# STM32H5F5 register map
File version: 1.0
CPU: CM33 r0p0, little endian, MPU, FPU, 4 interrupt priority bits
Registers are 32-bit, read-write, reset 0x0 unless marked. A register's access mark holds for its fields unless they carry their own. Offsets are from the block's base; [hi:lo] are bit positions; 'fields as' and 'values as' point back to an identical list.

## OCTOSPI1 — OCTOSPI1 register block
Base 0x47001400
Same registers: OCTOSPI2 0x47002400, OCTOSPI1_S 0x57001400, OCTOSPI2_S 0x57002400
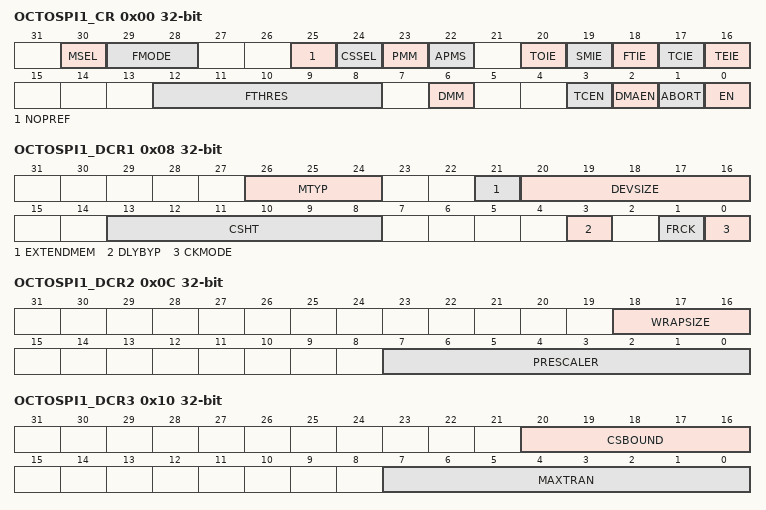
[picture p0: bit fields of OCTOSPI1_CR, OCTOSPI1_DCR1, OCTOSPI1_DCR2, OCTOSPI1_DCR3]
0x00 OCTOSPI1_CR — OCTOSPI control register
  [30] MSEL — External memory select
    0=External memory 1 selected (data exchanged over IO[3:0]); 1=External memory 2 selected (data exchanged over IO[7:4])
  [29:28] FMODE — Functional mode
    0=Indirect-write mode; 1=Indirect-read mode; 2=Automatic status-polling mode (relevant in regular-command protocol only); 3=Memory-mapped mode
  [25] NOPREF — No prefetch data
    0=Automatic prefetch enabled; 1=Automatic prefetch disabled
  [24] CSSEL — Chip-select selection
    0=NCS I/O manager input is copied to NCS1 I/O manager output; 1=NCS I/O manager input is copied to NCS2 I/O manager output
  [23] PMM — Polling match mode
    0=AND-match mode, SMF is set if all the unmasked bits received from the device match the corresponding bits in the match register; 1=OR-match mode, SMF is set if any of the unmasked bits received from the device matches its corresponding bit in the match register
  [22] APMS — Automatic status-polling mode stop
    0=Automatic status-polling mode is stopped only by abort or by disabling the OCTOSPI; 1=Automatic status-polling mode stops as soon as there is a match
  [20] TOIE — Timeout interrupt enable
    0=Interrupt disabled; 1=Interrupt enabled
  [19] SMIE — Status-match interrupt enable
    0=Interrupt disabled; 1=Interrupt enabled
  [18] FTIE — FIFO threshold interrupt enable
    0=Interrupt disabled; 1=Interrupt enabled
  [17] TCIE — Transfer complete interrupt enable
    0=Interrupt disabled; 1=Interrupt enabled
  [16] TEIE — Transfer error interrupt enable
    0=Interrupt disabled; 1=Interrupt enabled
  [12:8] FTHRES — FIFO threshold level
    0=FTF is set if there are one or more free bytes available to be written to in the FIFO inindirect-write mode, or if there are one or more valid bytes can be read from the FIFO inindirect-read mode; 1=FTF is set if there are two or more free bytes available to be written to in the FIFO inindirect-write mode, or if there are two or more valid bytes can be read from the FIFO inindirect-read mode; 31=FTF is set if there are 32 free bytes available to be written to in the FIFO in indirect-write mode, or if there are 32 valid bytes can be read from the FIFO in indirect-read mode
  [6] DMM — Dual-memory configuration
    0=Dual-memory configuration disabled; 1=Dual-memory configuration enabled
  [3] TCEN — Timeout counter enable
    0=The timeout counter is disabled, and thus the chip-select (NCS) remains active indefinitely after an access in memory-mapped mode; 1=The timeout counter is enabled, and thus the chip-select is released in the memory-mapped mode after TIMEOUT[15:0] cycles of external device inactivity
  [2] DMAEN — DMA enable
    0=DMA disabled for indirect mode; 1=DMA enabled for indirect mode
  [1] ABORT — Abort request
    0=No abort requested; 1=Abort requested
  [0] EN — Enable
    0=OCTOSPI disabled; 1=OCTOSPI enabled
0x08 OCTOSPI1_DCR1 — OCTOSPI device configuration register 1
  [26:24] MTYP — Memory type
    0=Micron mode, D0/D1 ordering in DTR 8-data-bit mode; 1=Macronix mode, D1/D0 ordering in DTR 8-data-bit mode; 2=Standard mode; 3=Macronix RAM mode, D1/D0 ordering in DTR 8-data-bit mode; 4=HyperBus memory mode, the protocol follows the HyperBusless thansup> less than/sup>specification; 5=HyperBus register mode, addressing register space
  [21] EXTENDMEM — Extended memory support
    0=NCS1 and NCS2 values depend from CSSEL bit in OCTOSPI_CR (software controlled); 1=NCS1 and NCS2 values depend from the address of transfer (hardware controlled)
  [20:16] DEVSIZE — Device size
  [13:8] CSHT — Chip-select high time
    0=NCS stays high for at least 1 cycle between external device commands; 1=NCS stays high for at least 2 cycles between external device commands; 63=NCS stays high for at least 64 cycles between external device commands
  [3] DLYBYP — Delay block bypass
    0=The internal sampling clock (called feedback clock) or the DQS data strobe external signal is delayed by the delay block (for more details on this block, refer to the dedicated section of the reference manual as it is not part of the OCTOSPI peripheral); 1=The delay block is bypassed, so the internal sampling clock or the DQS data strobe external signal is not affected by the delay block
  [1] FRCK — Free running clock
    0=CLK is not free running; 1=CLK is free running (always provided)
  [0] CKMODE — Clock mode 0/mode 3
    0=CLK must stay low while NCS is high (chip-select released); 1=CLK must stay high while NCS is high (chip-select released)
0x0C OCTOSPI1_DCR2 — OCTOSPI device configuration register 2
  [18:16] WRAPSIZE
    0=Wrapped reads are not supported by the memory; 2=External memory supports wrap size of 16 bytes; 3=External memory supports wrap size of 32 bytes; 4=External memory supports wrap size of 64 bytes; 5=External memory supports wrap size of 128 bytes
  [7:0] PRESCALER — Clock prescaler
    0=Fless thansub>CLKless than/sub> = Fless thansub>KERNELless than/sub>, kernel clock used directly as OCTOSPI CLK (prescaler bypassed); 1=Fless thansub>CLKless than/sub> = Fless thansub>KERNELless than/sub>/2
0x10 OCTOSPI1_DCR3 — OCTOSPI device configuration register 3
  [20:16] CSBOUND — NCS boundary
    0=NCS boundary disabled
  [7:0] MAXTRAN — Maximum transfer
    0=Maximum communication disabled
0x14 OCTOSPI1_DCR4 — OCTOSPI device configuration register 4
  [31:0] REFRESH — Refresh rate
    0=Refresh disabled
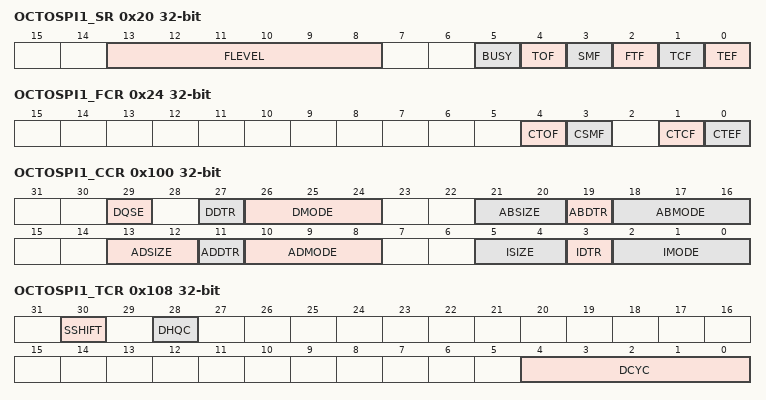
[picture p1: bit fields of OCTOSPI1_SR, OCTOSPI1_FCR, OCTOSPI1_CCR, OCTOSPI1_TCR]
0x20 OCTOSPI1_SR ro — OCTOSPI status register
  [13:8] FLEVEL — FIFO level
  [5] BUSY
  [4] TOF — Timeout flag
  [3] SMF — Status match flag
  [2] FTF — FIFO threshold flag
  [1] TCF — Transfer complete flag
  [0] TEF — Transfer error flag
0x24 OCTOSPI1_FCR wo — OCTOSPI flag clear register
  [4] CTOF — Clear timeout flag
  [3] CSMF — Clear status match flag
  [1] CTCF — Clear transfer complete flag
  [0] CTEF — Clear transfer error flag
0x40 OCTOSPI1_DLR — OCTOSPI data length register
  [31:0] DL — Data length
0x48 OCTOSPI1_AR — OCTOSPI address register
  [31:0] ADDRESS
0x50 OCTOSPI1_DR — OCTOSPI data register
  [31:0] DATA
0x80 OCTOSPI1_PSMKR — OCTOSPI polling status mask register
  [31:0] MASK — Status mask
    0=Bit n of the data received in automatic status-polling mode is masked and its value is not considered in the matching logic; 1=Bit n of the data received in automatic status-polling mode is unmasked and its value is considered in the matching logic
0x88 OCTOSPI1_PSMAR — OCTOSPI polling status match register
  [31:0] MATCH — Status match
0x90 OCTOSPI1_PIR — OCTOSPI polling interval register
  [15:0] INTERVAL — Polling interval
0x100 OCTOSPI1_CCR — OCTOSPI communication configuration register
  [29] DQSE — DQS enable
    0=DQS disabled; 1=DQS enabled
  [27] DDTR — Data double transfer rate
    0=DTR mode disabled for data phase; 1=DTR mode enabled for data phase
  [26:24] DMODE — Data mode
    0=No data; 1=Data on a single line; 2=Data on two lines; 3=Data on four lines; 4=Data on eight lines
  [21:20] ABSIZE — Alternate-byte size
    0=8-bit alternate bytes; 1=16-bit alternate bytes; 2=24-bit alternate bytes; 3=32-bit alternate bytes
  [19] ABDTR — Alternate- byte double transfer rate
    0=DTR mode disabled for the alternate-byte phase; 1=DTR mode enabled for the alternate-byte phase
  [18:16] ABMODE — Alternate-byte mode
    0=No alternate bytes; 1=Alternate bytes on a single line; 2=Alternate bytes on two lines; 3=Alternate bytes on four lines; 4=Alternate bytes on eight lines
  [13:12] ADSIZE — Address size
    0=8-bit address; 1=16-bit address; 2=24-bit address; 3=32-bit address
  [11] ADDTR — Address double transfer rate
    0=DTR mode disabled for the address phase; 1=DTR mode enabled for the address phase
  [10:8] ADMODE — Address mode
    0=No address; 1=Address on a single line; 2=Address on two lines; 3=Address on four lines; 4=Address on eight lines
  [5:4] ISIZE — Instruction size
    0=8-bit instruction; 1=16-bit instruction; 2=24-bit instruction; 3=32-bit instruction
  [3] IDTR — Instruction double transfer rate
    0=DTR mode disabled for the instruction phase; 1=DTR mode enabled for the instruction phase
  [2:0] IMODE — Instruction mode
    0=No instruction; 1=Instruction on a single line; 2=Instruction on two lines; 3=Instruction on four lines; 4=Instruction on eight lines
0x108 OCTOSPI1_TCR — OCTOSPI timing configuration register
  [30] SSHIFT — Sample shift
    0=No shift; 1=1/2 cycle shift
  [28] DHQC — Delay hold quarter cycle
    0=No delay hold; 1=1/4 cycle hold
  [4:0] DCYC — Number of dummy cycles
0x110 OCTOSPI1_IR — OCTOSPI instruction register
  [31:0] INSTRUCTION
0x120 OCTOSPI1_ABR — OCTOSPI alternate bytes register
  [31:0] ALTERNATE — Alternate bytes
0x130 OCTOSPI1_LPTR — OCTOSPI low-power timeout register
  [15:0] TIMEOUT — Timeout period
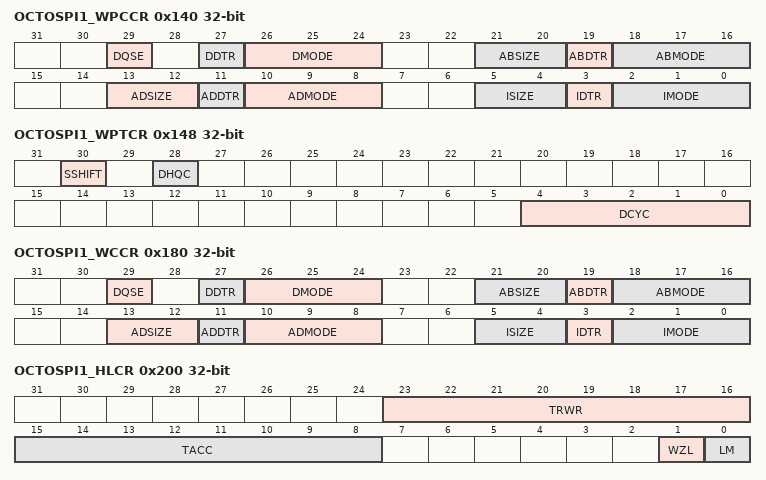
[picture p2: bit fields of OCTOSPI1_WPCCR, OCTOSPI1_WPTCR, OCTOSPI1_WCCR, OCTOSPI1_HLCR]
0x140 OCTOSPI1_WPCCR — OCTOSPI wrap communication configuration register
  [29] DQSE — DQS enable
    0=DQS disabled; 1=DQS enabled
  [27] DDTR — Data double transfer rate
    0=DTR mode disabled for the data phase; 1=DTR mode enabled for the data phase
  [26:24] DMODE — Data mode
    values as OCTOSPI1_CCR.DMODE
  [21:20] ABSIZE — Alternate-byte size
    values as OCTOSPI1_CCR.ABSIZE
  [19] ABDTR — Alternate-byte double transfer rate
    values as OCTOSPI1_CCR.ABDTR
  [18:16] ABMODE — Alternate-byte mode
    0=no alternate bytes; 1=alternate bytes on a single line; 2=alternate bytes on two lines; 3=alternate bytes on four lines; 4=alternate bytes on eight lines
  [13:12] ADSIZE — Address size
    values as OCTOSPI1_CCR.ADSIZE
  [11] ADDTR — Address double transfer rate
    0=DTR mode disabled for address phase; 1=DTR mode enabled for address phase
  [10:8] ADMODE — Address mode
    values as OCTOSPI1_CCR.ADMODE
  [5:4] ISIZE — Instruction size
    values as OCTOSPI1_CCR.ISIZE
  [3] IDTR — Instruction double transfer rate
    values as OCTOSPI1_CCR.IDTR
  [2:0] IMODE — Instruction mode
    values as OCTOSPI1_CCR.IMODE
0x148 OCTOSPI1_WPTCR — OCTOSPI wrap timing configuration register
  [30] SSHIFT — Sample shift
    0=No shift; 1=1/2 cycle shift
  [28] DHQC — Delay hold quarter cycle
    0=No quarter cycle delay; 1=1/4 cycle delay inserted
  [4:0] DCYC — Number of dummy cycles
0x150 OCTOSPI1_WPIR — OCTOSPI wrap instruction register
  [31:0] INSTRUCTION
0x160 OCTOSPI1_WPABR — OCTOSPI wrap alternate bytes register
  [31:0] ALTERNATE — Alternate bytes
0x180 OCTOSPI1_WCCR — OCTOSPI write communication configuration register
  [29] DQSE — DQS enable
    0=DQS disabled; 1=DQS enabled
  [27] DDTR — data double transfer rate
    values as OCTOSPI1_WPCCR.DDTR
  [26:24] DMODE — Data mode
    values as OCTOSPI1_CCR.DMODE
  [21:20] ABSIZE — Alternate-byte size
    values as OCTOSPI1_CCR.ABSIZE
  [19] ABDTR — Alternate bytes double transfer rate
    0=DTR mode disabled for alternate-bytes phase; 1=DTR mode enabled for alternate-bytes phase
  [18:16] ABMODE — Alternate-byte mode
    values as OCTOSPI1_CCR.ABMODE
  [13:12] ADSIZE — Address size
    values as OCTOSPI1_CCR.ADSIZE
  [11] ADDTR — Address double transfer rate
    values as OCTOSPI1_CCR.ADDTR
  [10:8] ADMODE — Address mode
    values as OCTOSPI1_CCR.ADMODE
  [5:4] ISIZE — Instruction size
    values as OCTOSPI1_CCR.ISIZE
  [3] IDTR — Instruction double transfer rate
    0=DTR mode disabled for instruction phase; 1=DTR mode enabled for instruction phase
  [2:0] IMODE — Instruction mode
    values as OCTOSPI1_CCR.IMODE
0x188 OCTOSPI1_WTCR — OCTOSPI write timing configuration register
  [4:0] DCYC — Number of dummy cycles
0x190 OCTOSPI1_WIR — OCTOSPI write instruction register
  [31:0] INSTRUCTION
0x1A0 OCTOSPI1_WABR — OCTOSPI write alternate bytes register
  [31:0] ALTERNATE — Alternate bytes
0x200 OCTOSPI1_HLCR — OCTOSPI HyperBus latency configuration register
  [23:16] TRWR — Read-write minimum recovery time
  [15:8] TACC — Access time
  [1] WZL — Write zero latency
    0=Latency on write accesses; 1=No latency on write accesses
  [0] LM — Latency mode
    0=Variable initial latency; 1=Fixed latency
